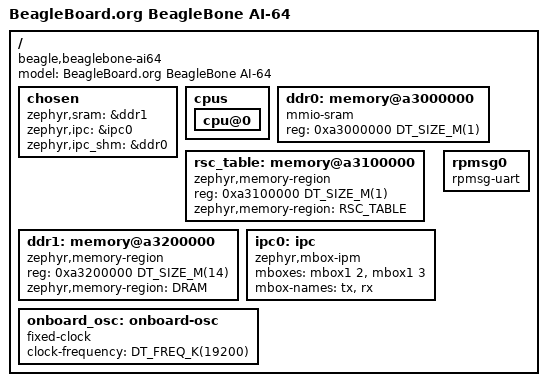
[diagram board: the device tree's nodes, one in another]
/* Copyright (c) 2026 Dhruv Menon <dhruvmenon1104@gmail.com>
 *
 * SPDX-License-Identifier: Apache-2.0
 */

/dts-v1/;

#include <ti/j721e_main_r5f0_1.dtsi>
#include <freq.h>

/ {
	model = "BeagleBoard.org BeagleBone AI-64";
	compatible = "beagle,beaglebone-ai64";

	chosen {
		zephyr,sram = &ddr1;
		zephyr,ipc = &ipc0;
		zephyr,ipc_shm = &ddr0;
	};

	cpus {
		cpu@0 {
			status = "okay";
		};
	};

	ddr0: memory@a3000000 {
		compatible = "mmio-sram";
		reg = <0xa3000000 DT_SIZE_M(1)>;
	};

	rsc_table: memory@a3100000 {
		compatible = "zephyr,memory-region", "mmio-sram";
		reg = <0xa3100000 DT_SIZE_M(1)>;
		zephyr,memory-region = "RSC_TABLE";
	};

	ddr1: memory@a3200000 {
		compatible = "zephyr,memory-region", "mmio-sram";
		reg = <0xa3200000 DT_SIZE_M(14)>;
		zephyr,memory-region = "DRAM";
	};

	ipc0: ipc {
		compatible = "zephyr,mbox-ipm";
		mboxes = <&mbox1 2>, <&mbox1 3>;
		mbox-names = "tx", "rx";
	};

	onboard_osc: onboard-osc {
		compatible = "fixed-clock";
		clock-frequency = <DT_FREQ_K(19200)>;
		#clock-cells = <0>;
	};

	rpmsg0: rpmsg0 {
		compatible = "rpmsg-uart";
	};
};
